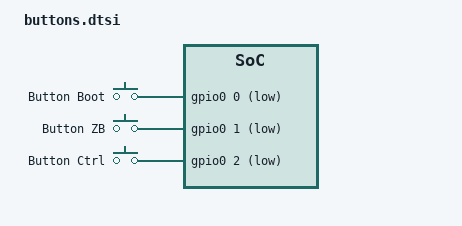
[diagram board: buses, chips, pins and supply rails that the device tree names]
/ {
	buttons {
		compatible = "gpio-keys";

		button0: button_0 {
			gpios = <&gpio0 0 (GPIO_PULL_UP | GPIO_ACTIVE_LOW)>;
			label = "Button Boot";
		};
		button1: button_1 {
			gpios = <&gpio0 1 (GPIO_PULL_UP | GPIO_ACTIVE_LOW)>;
			label = "Button ZB";
		};
		button2: button_2 {
			gpios = <&gpio0 2 (GPIO_PULL_UP | GPIO_ACTIVE_LOW)>;
			label = "Button Ctrl";
		};
	};
};

&gpio0 {
	status = "okay";
};
